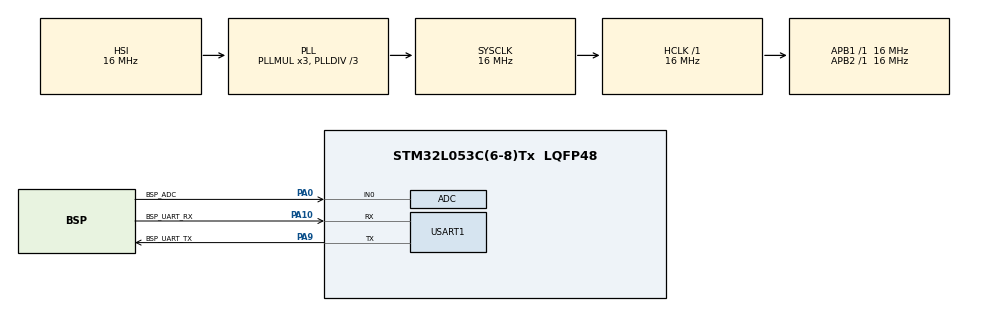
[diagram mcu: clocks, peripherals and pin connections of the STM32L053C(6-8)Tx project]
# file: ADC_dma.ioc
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ADC.ContinuousConvMode=ENABLE
ADC.Resolution=ADC_RESOLUTION_8B
Dma.ADC.0.Direction=DMA_PERIPH_TO_MEMORY
Dma.ADC.0.Instance=DMA1_Channel1
Dma.ADC.0.MemDataAlignment=DMA_MDATAALIGN_HALFWORD
Dma.ADC.0.MemInc=DMA_MINC_ENABLE
Dma.ADC.0.Mode=DMA_NORMAL
Dma.ADC.0.PeriphDataAlignment=DMA_PDATAALIGN_HALFWORD
Dma.ADC.0.PeriphInc=DMA_PINC_DISABLE
Dma.ADC.0.Priority=DMA_PRIORITY_LOW
Dma.Request0=ADC
Mcu.Family=STM32L0
Mcu.Name=STM32L053C(6-8)Tx
Mcu.Package=LQFP48
NVIC.DMA1_Channel1_IRQn=true\:0\:0\:false\:false\:true\:false\:true\:true
PA0.GPIO_Label=BSP_ADC
PA0.Mode=IN0
PA0.Signal=ADC_IN0
PA10.GPIO_Label=BSP_UART_RX
PA10.Mode=Asynchronous
PA10.Signal=USART1_RX
PA13.Mode=Serial_Wire
PA13.Signal=SYS_SWDIO
PA14.Mode=Serial_Wire
PA14.Signal=SYS_SWCLK
PA9.GPIO_Label=BSP_UART_TX
PA9.Mode=Asynchronous
PA9.Signal=USART1_TX
PC14-OSC32_IN.Mode=LSE-External-Oscillator
PC14-OSC32_IN.Signal=RCC_OSC32_IN
PC15-OSC32_OUT.Mode=LSE-External-Oscillator
PC15-OSC32_OUT.Signal=RCC_OSC32_OUT
PH0-OSC_IN.Mode=HSE-External-Oscillator
PH0-OSC_IN.Signal=RCC_OSC_IN
PH1-OSC_OUT.Mode=HSE-External-Oscillator
PH1-OSC_OUT.Signal=RCC_OSC_OUT
ProjectManager.HeapSize=0x200
ProjectManager.StackSize=0x400
ProjectManager.TargetToolchain=STM32CubeIDE
RCC.AHBFreq_Value=16000000
RCC.APB1Freq_Value=16000000
RCC.APB1TimFreq_Value=16000000
RCC.APB2Freq_Value=16000000
RCC.APB2TimFreq_Value=16000000
RCC.HCLKFreq_Value=16000000
RCC.HSE_VALUE=8000000
RCC.HSI16_VALUE=16000000
RCC.HSI48MClockSelection=RCC_USBCLKSOURCE_HSI48
RCC.HSI48_VALUE=48000000
RCC.HSI_VALUE=16000000
RCC.MSI_VALUE=2097000
RCC.PLLDIV=RCC_PLLDIV_3
RCC.RTCClockSelectionVirtual=RCC_RTCCLKSOURCE_LSE
RCC.SYSCLKFreq_VALUE=16000000
RCC.SYSCLKSource=RCC_SYSCLKSOURCE_PLLCLK
RCC.VCOOutputFreq_Value=48000000
USART1.VirtualMode-Asynchronous=VM_ASYNC
board=STM32L0538-DISCO

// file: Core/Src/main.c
/* USER CODE BEGIN Header */
/**
  ******************************************************************************
  * @file           : main.c
  * @brief          : Main program body
  ******************************************************************************
  * @attention
  *
  * Copyright (c) 2023 STMicroelectronics.
  * All rights reserved.
  *
  * This software is licensed under terms that can be found in the LICENSE file
  * in the root directory of this software component.
  * If no LICENSE file comes with this software, it is provided AS-IS.
  *
  ******************************************************************************
  */
/* USER CODE END Header */
#include "main.h"

/* USER CODE BEGIN Includes */
#include <stdio.h>
#include <string.h>
/* USER CODE END Includes */

ADC_HandleTypeDef hadc;
DMA_HandleTypeDef hdma_adc;

UART_HandleTypeDef huart1;

/* USER CODE BEGIN PV */
uint32_t adc_val;
char msg[10];
/* USER CODE END PV */

void SystemClock_Config(void);
static void MX_GPIO_Init(void);
static void MX_DMA_Init(void);
static void MX_USART1_UART_Init(void);
static void MX_ADC_Init(void);

int main(void)
{

  /* MCU Configuration--------------------------------------------------------*/

  /* Reset of all peripherals, Initializes the Flash interface and the Systick. */
  HAL_Init();

  /* Configure the system clock */
  SystemClock_Config();

  /* Initialize all configured peripherals */
  MX_GPIO_Init();
  MX_DMA_Init();
  MX_USART1_UART_Init();
  MX_ADC_Init();
  /* USER CODE BEGIN 2 */
HAL_ADCEx_Calibration_GetValue(&hadc, ADC_SINGLE_ENDED);
  /* USER CODE END 2 */

  /* Infinite loop */
  while (1)
  {

    /* USER CODE BEGIN 3 */
	  HAL_ADC_Start_DMA(&hadc,  &adc_val, 1);
	  HAL_Delay(1);
  }
  /* USER CODE END 3 */
}

void SystemClock_Config(void)
{
  RCC_OscInitTypeDef RCC_OscInitStruct = {0};
  RCC_ClkInitTypeDef RCC_ClkInitStruct = {0};
  RCC_PeriphCLKInitTypeDef PeriphClkInit = {0};

  /** Configure the main internal regulator output voltage
  */
  __HAL_PWR_VOLTAGESCALING_CONFIG(PWR_REGULATOR_VOLTAGE_SCALE1);

  /** Initializes the RCC Oscillators according to the specified parameters
  * in the RCC_OscInitTypeDef structure.
  */
  RCC_OscInitStruct.OscillatorType = RCC_OSCILLATORTYPE_HSI;
  RCC_OscInitStruct.HSIState = RCC_HSI_ON;
  RCC_OscInitStruct.HSICalibrationValue = RCC_HSICALIBRATION_DEFAULT;
  RCC_OscInitStruct.PLL.PLLState = RCC_PLL_ON;
  RCC_OscInitStruct.PLL.PLLSource = RCC_PLLSOURCE_HSI;
  RCC_OscInitStruct.PLL.PLLMUL = RCC_PLLMUL_3;
  RCC_OscInitStruct.PLL.PLLDIV = RCC_PLLDIV_3;
  if (HAL_RCC_OscConfig(&RCC_OscInitStruct) != HAL_OK)
  {
    Error_Handler();
  }

  /** Initializes the CPU, AHB and APB buses clocks
  */
  RCC_ClkInitStruct.ClockType = RCC_CLOCKTYPE_HCLK|RCC_CLOCKTYPE_SYSCLK
                              |RCC_CLOCKTYPE_PCLK1|RCC_CLOCKTYPE_PCLK2;
  RCC_ClkInitStruct.SYSCLKSource = RCC_SYSCLKSOURCE_PLLCLK;
  RCC_ClkInitStruct.AHBCLKDivider = RCC_SYSCLK_DIV1;
  RCC_ClkInitStruct.APB1CLKDivider = RCC_HCLK_DIV1;
  RCC_ClkInitStruct.APB2CLKDivider = RCC_HCLK_DIV1;

  if (HAL_RCC_ClockConfig(&RCC_ClkInitStruct, FLASH_LATENCY_0) != HAL_OK)
  {
    Error_Handler();
  }
  PeriphClkInit.PeriphClockSelection = RCC_PERIPHCLK_USART1;
  PeriphClkInit.Usart1ClockSelection = RCC_USART1CLKSOURCE_PCLK2;
  if (HAL_RCCEx_PeriphCLKConfig(&PeriphClkInit) != HAL_OK)
  {
    Error_Handler();
  }
}

static void MX_ADC_Init(void)
{

  ADC_ChannelConfTypeDef sConfig = {0};

  /** Configure the global features of the ADC (Clock, Resolution, Data Alignment and number of conversion)
  */
  hadc.Instance = ADC1;
  hadc.Init.OversamplingMode = DISABLE;
  hadc.Init.ClockPrescaler = ADC_CLOCK_SYNC_PCLK_DIV1;
  hadc.Init.Resolution = ADC_RESOLUTION_10B;
  hadc.Init.SamplingTime = ADC_SAMPLETIME_1CYCLE_5;
  hadc.Init.ScanConvMode = ADC_SCAN_DIRECTION_FORWARD;
  hadc.Init.DataAlign = ADC_DATAALIGN_RIGHT;
  hadc.Init.ContinuousConvMode = ENABLE;
  hadc.Init.DiscontinuousConvMode = DISABLE;
  hadc.Init.ExternalTrigConvEdge = ADC_EXTERNALTRIGCONVEDGE_NONE;
  hadc.Init.ExternalTrigConv = ADC_SOFTWARE_START;
  hadc.Init.DMAContinuousRequests = DISABLE;
  hadc.Init.EOCSelection = ADC_EOC_SINGLE_CONV;
  hadc.Init.Overrun = ADC_OVR_DATA_PRESERVED;
  hadc.Init.LowPowerAutoWait = DISABLE;
  hadc.Init.LowPowerFrequencyMode = DISABLE;
  hadc.Init.LowPowerAutoPowerOff = DISABLE;
  if (HAL_ADC_Init(&hadc) != HAL_OK)
  {
    Error_Handler();
  }

  /** Configure for the selected ADC regular channel to be converted.
  */
  sConfig.Channel = ADC_CHANNEL_0;
  sConfig.Rank = ADC_RANK_CHANNEL_NUMBER;
  if (HAL_ADC_ConfigChannel(&hadc, &sConfig) != HAL_OK)
  {
    Error_Handler();
  }

}

static void MX_USART1_UART_Init(void)
{

  huart1.Instance = USART1;
  huart1.Init.BaudRate = 115200;
  huart1.Init.WordLength = UART_WORDLENGTH_8B;
  huart1.Init.StopBits = UART_STOPBITS_1;
  huart1.Init.Parity = UART_PARITY_NONE;
  huart1.Init.Mode = UART_MODE_TX_RX;
  huart1.Init.HwFlowCtl = UART_HWCONTROL_NONE;
  huart1.Init.OverSampling = UART_OVERSAMPLING_16;
  huart1.Init.OneBitSampling = UART_ONE_BIT_SAMPLE_DISABLE;
  huart1.AdvancedInit.AdvFeatureInit = UART_ADVFEATURE_NO_INIT;
  if (HAL_UART_Init(&huart1) != HAL_OK)
  {
    Error_Handler();
  }

}

static void MX_DMA_Init(void)
{

  /* DMA controller clock enable */
  __HAL_RCC_DMA1_CLK_ENABLE();

  /* DMA interrupt init */
  /* DMA1_Channel1_IRQn interrupt configuration */
  HAL_NVIC_SetPriority(DMA1_Channel1_IRQn, 0, 0);
  HAL_NVIC_EnableIRQ(DMA1_Channel1_IRQn);

}

static void MX_GPIO_Init(void)
{

  /* GPIO Ports Clock Enable */
  __HAL_RCC_GPIOC_CLK_ENABLE();
  __HAL_RCC_GPIOH_CLK_ENABLE();
  __HAL_RCC_GPIOA_CLK_ENABLE();

}

/* USER CODE BEGIN 4 */
void HAL_ADC_ConvCpltCallback(ADC_HandleTypeDef *hadc){
	adc_val = HAL_ADC_GetValue(hadc);
	// Convert to string and print
	sprintf(msg, "%lu\r\n", adc_val);
	HAL_UART_Transmit(&huart1, (uint8_t*) msg, strlen(msg), 1000);
}
/* USER CODE END 4 */

void Error_Handler(void)
{
  __disable_irq();
  while (1)
  {
  }
}
